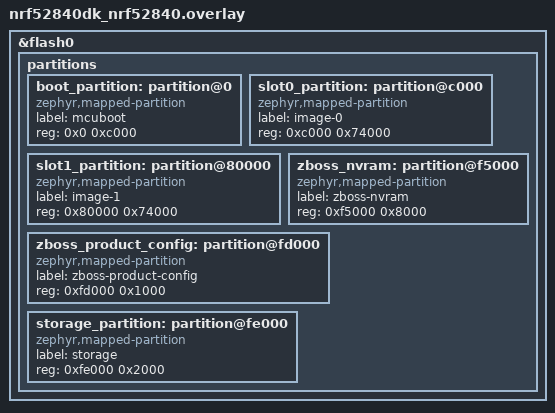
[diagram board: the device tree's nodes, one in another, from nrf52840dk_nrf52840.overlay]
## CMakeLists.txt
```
#
# Copyright (c) 2024-2026 Nordic Semiconductor ASA
#
# SPDX-License-Identifier: LicenseRef-Nordic-5-Clause
#

cmake_minimum_required(VERSION 3.20.0)

find_package(Zephyr REQUIRED HINTS $ENV{ZEPHYR_BASE})

project("Zigbee Light Switch")

target_sources(app PRIVATE
	src/main.cpp
	src/app_task_zigbee.c
	src/zboss_mem_globals.c
)

target_include_directories(app PRIVATE include)

target_sources_ifdef(CONFIG_BT_NUS app PRIVATE
	src/nus_cmd.c
)

# LTO link: zb_memconfig.o from prebuilts is plain ELF (weak gc_*); strong gc_*
# in zb_mem_config_context.h must not be LTO bytecode or ld warns about symbol size.
if(CONFIG_LTO)
	set_source_files_properties(
		src/zboss_mem_globals.c
		PROPERTIES COMPILE_OPTIONS -fno-lto
	)
endif()
```

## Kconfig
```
#
# Copyright (c) 2024-2026 Nordic Semiconductor ASA
#
# SPDX-License-Identifier: LicenseRef-Nordic-5-Clause
#

if ZIGBEE_BT_DFU

config BT_DEVICE_NAME
	default "Zigbee_Switch"

endif # ZIGBEE_BT_DFU

config MPSL_THREAD_COOP_PRIO
	default 8

menu "Zephyr Kernel"
source "Kconfig.zephyr"
endmenu

module = NUS_CMD
module-str = NUS command
source "${ZEPHYR_BASE}/subsys/logging/Kconfig.template.log_config"


config LIGHT_SWITCH_CONFIGURE_TX_POWER
	bool "Configure TX power"
	default y
	help
		Enable this option to configure TX power for the sample.

config LIGHT_SWITCH_TX_POWER
	int "TX power"
	depends on LIGHT_SWITCH_CONFIGURE_TX_POWER
	default 0
	help
		TX power level in dBm.

config LIGHT_SWITCH_LOW_POWER
	bool "Low power mode"
	default y
	depends on PM_DEVICE
	help
		Enable low power mode for the Light Switch sample.
		This enables sleepy behavior and disables LEDs for power savings.
```

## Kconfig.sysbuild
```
#
# Copyright (c) 2024-2026 Nordic Semiconductor
#
# SPDX-License-Identifier: LicenseRef-Nordic-5-Clause
#

config NRF_DEFAULT_IPC_RADIO
	default y

# Enable IEEE802.15.4 serialization to network core for Zigbee
config NETCORE_IPC_RADIO_IEEE802154
	default y if SOC_SERIES_NRF53

if BOOTLOADER_MCUBOOT

#### DFU multi-image support
config DFU_MULTI_IMAGE_PACKAGE_BUILD
	default y

config DFU_MULTI_IMAGE_PACKAGE_APP
	default y

#### DFU dual core configuration
if SOC_SERIES_NRF53

config PM_EXTERNAL_FLASH_MCUBOOT_SECONDARY
	default y

config MCUBOOT_UPDATEABLE_IMAGES
	default 2

choice MCUBOOT_MODE
	default MCUBOOT_MODE_OVERWRITE_ONLY
endchoice

config SECURE_BOOT_NETCORE
	default y

config NETCORE_APP_UPDATE
	default y

config DFU_MULTI_IMAGE_PACKAGE_NET
	default y

config MCUBOOT_NRF53_MULTI_IMAGE_UPDATE
	default y if NETCORE_APP_UPDATE

endif # SOC_SERIES_NRF53

endif # BOOTLOADER_MCUBOOT

source "${ZEPHYR_BASE}/share/sysbuild/Kconfig"
```

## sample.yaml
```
sample:
  description: Zigbee dimmable light switch based on ZBOSS stack
  name: Zigbee Light switch
common:
  tags:
    - ci_build
    - smoke
    - sysbuild
    - ci_samples_zigbee
tests:
  sample.zigbee.light_switch:
    sysbuild: true
    build_only: true
    integration_platforms:
      - nrf52840dk/nrf52840
      - nrf54l15dk/nrf54l15/cpuapp
      - nrf54lc10dk/nrf54lc10a/cpuapp
      - nrf54lm20dk/nrf54lm20b/cpuapp
      - nrf54lm20dongle/nrf54lm20b/cpuapp
    platform_allow:
      - nrf52840dk/nrf52840
      - nrf5340dk/nrf5340/cpuapp
      - nrf54l15dk/nrf54l10/cpuapp
      - nrf54l15dk/nrf54l15/cpuapp
      - nrf54lc10dk/nrf54lc10a/cpuapp
      - nrf54lm20dk/nrf54lm20a/cpuapp
      - nrf54lm20dk/nrf54lm20b/cpuapp
      - nrf54lm20dongle/nrf54lm20b/cpuapp
  sample.zigbee.light_switch.multiprotocol:
    sysbuild: true
    build_only: true
    extra_args: OVERLAY_CONFIG=overlay-multiprotocol_ble.conf
    integration_platforms:
      - nrf5340dk/nrf5340/cpuapp
      - nrf54l15dk/nrf54l15/cpuapp
      - nrf54lm20dk/nrf54lm20b/cpuapp
      - nrf54lm20dongle/nrf54lm20b/cpuapp
    platform_allow:
      - nrf52840dk/nrf52840
      - nrf5340dk/nrf5340/cpuapp
      - nrf54l15dk/nrf54l10/cpuapp
      - nrf54l15dk/nrf54l15/cpuapp
      - nrf54lc10dk/nrf54lc10a/cpuapp
      - nrf54lm20dk/nrf54lm20a/cpuapp
      - nrf54lm20dk/nrf54lm20b/cpuapp
      - nrf54lm20dongle/nrf54lm20b/cpuapp
  sample.zigbee.light_switch.io_shell:
    sysbuild: true
    build_only: true
    extra_args: light_switch_SNIPPET=io_shell
    integration_platforms:
      - nrf54lm20dongle/nrf54lm20b/cpuapp
    platform_allow:
      - nrf54lm20dongle/nrf54lm20b/cpuapp
  sample.zigbee.light_switch.with_shell:
    sysbuild: true
    build_only: true
    extra_args:
      - CONFIG_ZIGBEE_SHELL=y
      - CONFIG_ZIGBEE_SHELL_DEBUG_CMD=y
      - CONFIG_ZIGBEE_LOGGER_EP=n
      - CONFIG_ZIGBEE_SHELL_ENDPOINT=1
      - CONFIG_LOG_MODE_DEFERRED=y
      - CONFIG_ZIGBEE_TOUCHLINK_INITIATOR=y
    platform_allow:
      - nrf52840dk/nrf52840
      - nrf5340dk/nrf5340/cpuapp
      - nrf54l15dk/nrf54l10/cpuapp
      - nrf54l15dk/nrf54l15/cpuapp
      - nrf54lc10dk/nrf54lc10a/cpuapp
      - nrf54lm20dk/nrf54lm20a/cpuapp
      - nrf54lm20dk/nrf54lm20b/cpuapp
    tags:
      - no_integration
      - shell
  sample.zigbee.light_switch.fota:
    sysbuild: true
    build_only: true
    extra_args:
      - FILE_SUFFIX=fota
      - SNIPPET=zigbee_fota
    integration_platforms:
      - nrf52840dk/nrf52840
      - nrf54l15dk/nrf54l15/cpuapp
      - nrf54lc10dk/nrf54lc10a/cpuapp
      - nrf54lm20dk/nrf54lm20b/cpuapp
    platform_allow:
      - nrf52840dk/nrf52840
      - nrf5340dk/nrf5340/cpuapp
      - nrf54l15dk/nrf54l10/cpuapp
      - nrf54l15dk/nrf54l15/cpuapp
      - nrf54lc10dk/nrf54lc10a/cpuapp
      - nrf54lm20dk/nrf54lm20a/cpuapp
      - nrf54lm20dk/nrf54lm20b/cpuapp
  sample.zigbee.light_switch.fota_and_multiprotocol:
    sysbuild: true
    build_only: true
    extra_args:
      - FILE_SUFFIX=fota
      - SNIPPET=zigbee_fota
      - OVERLAY_CONFIG=overlay-multiprotocol_ble.conf
    integration_platforms:
      - nrf5340dk/nrf5340/cpuapp
      - nrf54l15dk/nrf54l15/cpuapp
      - nrf54lm20dk/nrf54lm20b/cpuapp
    platform_allow:
      - nrf5340dk/nrf5340/cpuapp
      - nrf54l15dk/nrf54l15/cpuapp
      - nrf54lm20dk/nrf54lm20a/cpuapp
      - nrf54lm20dk/nrf54lm20b/cpuapp
  sample.zigbee.light_switch.low_power:
    sysbuild: true
    build_only: true
    extra_args:
      - light_switch_SNIPPET="low_power"
    integration_platforms:
      - nrf52840dk/nrf52840
      - nrf5340dk/nrf5340/cpuapp
      - nrf54l15dk/nrf54l15/cpuapp
      - nrf54lm20dk/nrf54lm20b/cpuapp
    platform_allow:
      - nrf52840dk/nrf52840
      - nrf5340dk/nrf5340/cpuapp
      - nrf54l15dk/nrf54l10/cpuapp
      - nrf54l15dk/nrf54l15/cpuapp
      - nrf54lc10dk/nrf54lc10a/cpuapp
      - nrf54lm20dk/nrf54lm20a/cpuapp
      - nrf54lm20dk/nrf54lm20b/cpuapp
```

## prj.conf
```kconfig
#
# Copyright (c) 2024 Nordic Semiconductor ASA
#
# SPDX-License-Identifier: LicenseRef-Nordic-5-Clause
#

CONFIG_NCS_SAMPLES_DEFAULTS=y

CONFIG_UART_INTERRUPT_DRIVEN=y
CONFIG_SERIAL=y
CONFIG_GPIO=y

# Make sure printk is not printing to the UART console
CONFIG_CONSOLE=y
CONFIG_UART_CONSOLE=y

CONFIG_HEAP_MEM_POOL_SIZE=2048

CONFIG_ZIGBEE_ADD_ON=y
CONFIG_ZIGBEE_APP_UTILS=y
CONFIG_ZIGBEE_ROLE_END_DEVICE=y

# Enable DK LED and Buttons library
CONFIG_DK_LIBRARY=y
# Enable API for powering down unused RAM parts
CONFIG_RAM_POWER_DOWN_LIBRARY=y
```

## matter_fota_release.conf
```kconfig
#
# Copyright (c) 2026 Nordic Semiconductor ASA
#
# SPDX-License-Identifier: LicenseRef-Nordic-5-Clause
#
# Release configuration for combined Zigbee + Matter + Thread (PoC)
# Strips logging/console/debug and enables size optimizations.

#######################
# Release Optimizations
#######################

CONFIG_USE_SEGGER_RTT=n
CONFIG_SHELL=n
CONFIG_OPENTHREAD_SHELL=n
CONFIG_CONSOLE=n
CONFIG_UART_CONSOLE=n
CONFIG_SERIAL=n
CONFIG_UART_INTERRUPT_DRIVEN=n
CONFIG_LOG=n
CONFIG_LOG_MODE_MINIMAL=n
CONFIG_ASSERT_VERBOSE=n
CONFIG_ASSERT_NO_FILE_INFO=y
CONFIG_PRINTK=n
CONFIG_PRINTK_SYNC=n
CONFIG_BOOT_BANNER=n

# TODO: Enable LTO to decrease the flash usage after testing
# CONFIG_LTO=y
# CONFIG_ISR_TABLES_LOCAL_DECLARATION=y

CONFIG_SIZE_OPTIMIZATIONS=y
CONFIG_COMPILER_OPT="-Os"
```

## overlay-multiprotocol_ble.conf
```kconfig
#
# Copyright (c) 2024 Nordic Semiconductor ASA
#
# SPDX-License-Identifier: LicenseRef-Nordic-5-Clause
#

# BLE configuration
CONFIG_BT=y
CONFIG_BT_SMP=y
CONFIG_BT_PERIPHERAL=y
CONFIG_BT_DEVICE_NAME="Zigbee_Switch"
CONFIG_BT_DEVICE_APPEARANCE=833
CONFIG_BT_MAX_CONN=1
CONFIG_BT_MAX_PAIRED=1
CONFIG_BT_PHY_UPDATE=n

# Enable the NUS service
CONFIG_BT_NUS=y

# Enable bonding
CONFIG_SETTINGS=y
CONFIG_BT_SETTINGS=y

# BLE uses ECB peripheral directly
CONFIG_CRYPTO=n
CONFIG_CRYPTO_NRF_ECB=n
```

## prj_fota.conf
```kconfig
#
# Copyright (c) 2020 Nordic Semiconductor ASA
#
# SPDX-License-Identifier: LicenseRef-Nordic-5-Clause
#

CONFIG_NCS_SAMPLES_DEFAULTS=y

CONFIG_UART_INTERRUPT_DRIVEN=y
CONFIG_SERIAL=y
CONFIG_GPIO=y

# Make sure printk is not printing to the UART console
CONFIG_CONSOLE=y
CONFIG_UART_CONSOLE=y

CONFIG_HEAP_MEM_POOL_SIZE=2048

CONFIG_ZIGBEE_ADD_ON=y
CONFIG_ZIGBEE_APP_UTILS=y
CONFIG_ZIGBEE_ROLE_END_DEVICE=y

# Enable DK LED and Buttons library
CONFIG_DK_LIBRARY=y
# Enable API for powering down unused RAM parts
CONFIG_RAM_POWER_DOWN_LIBRARY=y


#######################
# Zigbee FOTA overlay #
#######################

# Enable Zigbee FOTA library
CONFIG_ZIGBEE_FOTA=y
CONFIG_ZIGBEE_FOTA_HW_VERSION=52
CONFIG_ZIGBEE_FOTA_ENDPOINT=5
CONFIG_MCUBOOT_IMGTOOL_SIGN_VERSION="1.2.3"
CONFIG_ZIGBEE_FOTA_COMMENT="light_switch"
CONFIG_ZIGBEE_FOTA_DOWNLOAD_RESUME=y

# Ensure an MCUboot-compatible binary is generated.
CONFIG_IMG_MANAGER=y
CONFIG_STREAM_FLASH=y
CONFIG_DFU_TARGET_MCUBOOT=y
CONFIG_IMG_ERASE_PROGRESSIVELY=y
CONFIG_ZIGBEE_FOTA_PROGRESS_EVT=y

# Increase the number of RX buffers
CONFIG_NRF_802154_RX_BUFFERS=32
```

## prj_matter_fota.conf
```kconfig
#
# Copyright (c) 2026 Nordic Semiconductor ASA
#
# SPDX-License-Identifier: LicenseRef-Nordic-5-Clause
#

CONFIG_NCS_SAMPLES_DEFAULTS=y

CONFIG_UART_INTERRUPT_DRIVEN=y
CONFIG_SERIAL=y
CONFIG_GPIO=y

CONFIG_CONSOLE=y
CONFIG_UART_CONSOLE=y

CONFIG_HEAP_MEM_POOL_SIZE=2048
CONFIG_MAIN_STACK_SIZE=10240
CONFIG_MAIN_THREAD_PRIORITY=7

#######################
# Zigbee Configuration
#######################

CONFIG_ZIGBEE_ADD_ON=y
CONFIG_ZIGBEE_APP_UTILS=y
CONFIG_ZIGBEE_APP_UTILS_LOG_LEVEL_INF=y
CONFIG_ZIGBEE_ROLE_END_DEVICE=y

CONFIG_DK_LIBRARY=y

# Touchlink initiator role for the combined Matter build
# CONFIG_ZIGBEE_TOUCHLINK_INITIATOR=y

CONFIG_RAM_POWER_DOWN_LIBRARY=y

CONFIG_ZBOSS_OSIF_LOG_LEVEL_INF=y
CONFIG_ZIGBEE_MATTER_COEXISTENCE_LOG_LEVEL_INF=y

#######################
# Matter Configuration
#######################

CONFIG_CHIP=y
CONFIG_CHIP_PROJECT_CONFIG="include/chip_project_config.h"
CONFIG_CHIP_DEVICE_PRODUCT_NAME="Matter Zigbee Light Switch"

CONFIG_NCS_SAMPLE_MATTER_ZAP_FILE_PATH="${APPLICATION_CONFIG_DIR}/src/default_zap/light_switch.zap"

CONFIG_CHIP_DEVICE_PRODUCT_ID=32772
CONFIG_STD_CPP17=y

CONFIG_CHIP_ENABLE_PAIRING_AUTOSTART=y
CONFIG_CHIP_BLE_EXT_ADVERTISING=y
CONFIG_CHIP_BLE_ADVERTISING_DURATION=60

CONFIG_BT_DEVICE_NAME="MatterZigbeeSw"

CONFIG_THREAD_NAME=y
CONFIG_MPU_STACK_GUARD=y
CONFIG_RESET_ON_FATAL_ERROR=n

# Reduce application size
CONFIG_USE_SEGGER_RTT=n

# Increase system workqueue stack for combined protocols (with Thread)
CONFIG_SYSTEM_WORKQUEUE_STACK_SIZE=6144

# Must be a preemptible priority (0–15), not cooperative (-1). With -1, ZBOSS is
# coop priority -1 and is outranked by MPSL Work (prio -8), so it never runs.
# State 128 = _THREAD_QUEUED (runnable); ZBOSS stays queued and never gets CPU.
CONFIG_ZBOSS_DEFAULT_THREAD_PRIORITY=1
CONFIG_ZBOSS_DEFAULT_THREAD_STACK_SIZE=6144

# Libc malloc arena required for Zigbee + Matter coexistence.
# - 0: no libc heap -> Matter init fails (malloc/calloc used during init).
# - -1: "all remaining RAM" -> on this build the computed heap extends past
#        valid SRAM and faults at first free().
# - Fixed value sized for Matter + Thread + Zigbee (empirical):
#   ~96 KB covers Matter CASE session, Thread buffers, and Zigbee allocations
#   without running the heap off the end of usable SRAM.
CONFIG_COMMON_LIBC_MALLOC_ARENA_SIZE=-1

## PoC Configuration ##
# Keep Matter shell disabled to avoid getopt conflicts
CONFIG_CHIP_LIB_SHELL=n
CONFIG_NCS_SAMPLE_MATTER_TEST_SHELL=n

# Radio dispatcher
CONFIG_NRF_802154_CALLBACKS_DISPATCHER=y
CONFIG_NRF_802154_DRV_REINIT_ENABLED=y

# We need it to disable ZBOSS thread
CONFIG_ZIGBEE_DEBUG_FUNCTIONS=y

CONFIG_CHIP_FACTORY_DATA_BUILD=y

# DFU over Bluetooth LE SMP
CONFIG_CHIP_DFU_OVER_BT_SMP=y
```

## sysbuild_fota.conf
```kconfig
#
# Copyright (c) 2024 Nordic Semiconductor ASA
#
# SPDX-License-Identifier: LicenseRef-Nordic-5-Clause
#

# Disable partition manager
SB_CONFIG_PARTITION_MANAGER=n

SB_CONFIG_BOOTLOADER_MCUBOOT=y
SB_CONFIG_MCUBOOT_MODE_OVERWRITE_ONLY=y
SB_CONFIG_MCUBOOT_COMPRESSED_IMAGE_SUPPORT=y
```

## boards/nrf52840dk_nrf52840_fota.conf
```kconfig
#
# Copyright (c) 2022 Nordic Semiconductor ASA
#
# SPDX-License-Identifier: LicenseRef-Nordic-5-Clause
#

# Networking
CONFIG_MPSL=y
```

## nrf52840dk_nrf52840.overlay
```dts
&flash0 {
	partitions {
		boot_partition: partition@0 {
			compatible = "zephyr,mapped-partition";
			label = "mcuboot";
			reg = <0x0 0xc000>;
		};

		slot0_partition: partition@c000 {
			compatible = "zephyr,mapped-partition";
			label = "image-0";
			reg = <0xc000 0x74000>;
		};

		slot1_partition: partition@80000 {
			compatible = "zephyr,mapped-partition";
			label = "image-1";
			reg = <0x80000 0x74000>;
		};

		zboss_nvram: partition@f5000 {
			compatible = "zephyr,mapped-partition";
			label = "zboss-nvram";
			reg = <0xf5000 0x8000>;
		};

		zboss_product_config: partition@fd000 {
			compatible = "zephyr,mapped-partition";
			label = "zboss-product-config";
			reg = <0xfd000 0x1000>;
		};

		storage_partition: partition@fe000 {
			compatible = "zephyr,mapped-partition";
			label = "storage";
			reg = <0xfe000 0x2000>;
		};
	};
};
```

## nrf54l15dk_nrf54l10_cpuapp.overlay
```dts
&cpuapp_rram {
	partitions {
		slot0_partition: partition@0 {
			compatible = "zephyr,mapped-partition";
			label = "image-0";
			reg = <0x0 0xf4000>;
		};

		zboss_nvram: partition@f4000 {
			compatible = "zephyr,mapped-partition";
			label = "zboss-nvram";
			reg = <0xf4000 0x8000>;
		};

		zboss_product_config: partition@fc000 {
			compatible = "zephyr,mapped-partition";
			label = "zboss-product-config";
			reg = <0xfc000 0x1000>;
		};
	};
};
```

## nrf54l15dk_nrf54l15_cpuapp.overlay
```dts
&cpuapp_rram {
	partitions {
		boot_partition: partition@0 {
			compatible = "zephyr,mapped-partition";
			label = "mcuboot";
			reg = <0x0 0x14000>;
		};

		slot0_partition: partition@14000 {
			compatible = "zephyr,mapped-partition";
			label = "image-0";
			reg = <0x14000 0xaf000>;
		};

		slot1_partition: partition@c3000 {
			compatible = "zephyr,mapped-partition";
			label = "image-1";
			reg = <0xc3000 0xaf000>;
		};

		zboss_nvram: partition@172000 {
			compatible = "zephyr,mapped-partition";
			label = "zboss-nvram";
			reg = <0x172000 0x8000>;
		};

		zboss_product_config: partition@17a000 {
			compatible = "zephyr,mapped-partition";
			label = "zboss-product-config";
			reg = <0x17a000 0x1000>;
		};

		storage_partition: partition@17b000 {
			compatible = "zephyr,mapped-partition";
			label = "storage";
			reg = <0x17b000 0x2000>;
		};
	};
};
```

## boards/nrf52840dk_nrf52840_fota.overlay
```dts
/*
 * Copyright (c) 2026 Nordic Semiconductor ASA
 *
 * SPDX-License-Identifier: LicenseRef-Nordic-5-Clause
 */

#include <nrf52840_partitions.dtsi>
#include <ext_flash/nrf52840dk_partitions.dtsi>

/ {
	chosen {
		ncs,zigbee-timer = &timer2;
	};
};

&timer2 {
	status = "okay";
};
```

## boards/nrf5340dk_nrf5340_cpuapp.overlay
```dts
/*
 * Copyright (c) 2025 Nordic Semiconductor ASA
 *
 * SPDX-License-Identifier: LicenseRef-Nordic-5-Clause
 */

/ {
	chosen {
		nordic,pm-ext-flash = &mx25r64;
		ncs,zigbee-timer = &timer2;
	};
};

&timer2 {
	status = "okay";
};
```

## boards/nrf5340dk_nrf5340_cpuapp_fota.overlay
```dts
/*
 * Copyright (c) 2026 Nordic Semiconductor ASA
 *
 * SPDX-License-Identifier: LicenseRef-Nordic-5-Clause
 */

#include <nrf5340_cpuapp_partitions.dtsi>
#include <ext_flash/nrf5340dk_cpuapp_partitions.dtsi>

/ {
	chosen {
		ncs,zigbee-timer = &timer2;
	};
};

&timer2 {
	status = "okay";
};
```

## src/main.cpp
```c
/*
 * Copyright (c) 2024-2026 Nordic Semiconductor ASA
 *
 * SPDX-License-Identifier: LicenseRef-Nordic-5-Clause
 */

/** @file
 *
 * @brief Zigbee light switch entry point.
 */

#include "app_task_zigbee.h"

int main(void)
{
	return ZigbeeStart();
}
```

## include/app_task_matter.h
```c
/*
 * Copyright (c) 2026 Nordic Semiconductor ASA
 *
 * SPDX-License-Identifier: LicenseRef-Nordic-5-Clause
 */

#pragma once

#include "board/board.h"

#include <platform/CHIPDeviceLayer.h>

struct k_timer;
struct Identify;

class AppTask {
public:
	static AppTask &Instance()
	{
		static AppTask sAppTask;
		return sAppTask;
	};

	CHIP_ERROR StartApp();

	void UpdateClusterState();

private:
	enum Timer : uint8_t { DimmerTrigger, Dimmer };

	CHIP_ERROR Init();

	static void DimmerTriggerEventHandler();
	static void TimerEventHandler(const Timer &event);
	static void ButtonEventHandler(Nrf::ButtonState state, Nrf::ButtonMask hasChanged);

	static void StartTimer(Timer, uint32_t);
	static void CancelTimer(Timer);
	static void UserTimerTimeoutCallback(k_timer *timer);
};
```

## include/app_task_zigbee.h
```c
/*
 * Copyright (c) 2026 Nordic Semiconductor ASA
 *
 * SPDX-License-Identifier: LicenseRef-Nordic-5-Clause
 */

#ifndef APP_TASK_ZIGBEE_H
#define APP_TASK_ZIGBEE_H 1

#include <stdint.h>

#ifdef __cplusplus
extern "C" {
#endif

int ZigbeeStart(void);

#ifdef CONFIG_ZIGBEE_MATTER_COEXISTENCE
/**
 * @brief Button handler for Zigbee in combined Matter+Zigbee builds.
 *
 * Processes button events when Zigbee protocol is active.
 * Checks protocol state and returns early if Matter is active.
 *
 * @param button_state  Bitmask containing buttons state.
 * @param has_changed   Bitmask containing buttons that changed state.
 */
void zb_button_handler(uint32_t button_state, uint32_t has_changed);

/**
 * @brief Register the Zigbee button handler with DK library.
 *
 * Must be called after Matter's Board::Init() to chain the Zigbee handler.
 */
void zb_register_button_handler(void);
#endif /* CONFIG_ZIGBEE_MATTER_COEXISTENCE */

#ifdef __cplusplus
}
#endif

#endif /* APP_TASK_ZIGBEE_H */
```

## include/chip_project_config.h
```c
/*
 * Copyright (c) 2022-2026 Nordic Semiconductor ASA
 *
 * SPDX-License-Identifier: LicenseRef-Nordic-5-Clause
 */

#pragma once

#define CHIP_CONFIG_CONTROLLER_MAX_ACTIVE_DEVICES 2

#ifndef CHIP_CONFIG_MAX_PEER_NODES
#define CHIP_CONFIG_MAX_PEER_NODES 8
#endif
```

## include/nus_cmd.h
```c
/*
 * Copyright (c) 2024 Nordic Semiconductor ASA
 *
 * SPDX-License-Identifier: LicenseRef-Nordic-5-Clause
 */

/**
 * @file nus_cmd.h
 *
 * @brief APIs for NUS Command Service.
 */

#ifndef __NUS_CMD_H__
#define __NUS_CMD_H__

#include <stddef.h>

/** @brief Type indicates function called when Bluetooth LE connection
 *         is established.
 *
 * @param[in] item pointer to work item.
 */
typedef void (*nus_connection_cb_t)(struct k_work *item);

/** @brief Type indicates function called when Bluetooth LE connection is ended.
 *
 * @param[in] item pointer to work item.
 */
typedef void (*nus_disconnection_cb_t)(struct k_work *item);

/** @brief NUS command entry.
 */
struct nus_entry {
	const char *cmd;        /**< Command string. */
	struct k_work work;     /**< Command work item. */
};

/**@brief Macro to initialise (bind) command string to work handler.
 */
#define NUS_COMMAND(_cmd, _handler)		      \
	{					      \
		.work = Z_WORK_INITIALIZER(_handler), \
		.cmd = _cmd,			      \
	}					      \

/**@brief Function to initialise NUS Command service.
 *
 * @param[in] on_connect Callback that will be called when central connects to
 *			 the NUS service.
 * @param[in] on_disconnect Callback that will be called when BLE central
 *			    disconnects from the NUS service.
 * @param[in] command_set   A pointer to an array with NUS commands.
 * @param[in] command_count Number of entries in @p command_set.
 */
void nus_cmd_init(nus_connection_cb_t on_connect,
		  nus_disconnection_cb_t on_disconnect,
		  struct nus_entry *command_set, size_t command_count);

#endif
```

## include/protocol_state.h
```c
/*
 * Copyright (c) 2024-2026 Nordic Semiconductor ASA
 *
 * SPDX-License-Identifier: LicenseRef-Nordic-5-Clause
 */

#ifndef PROTOCOL_STATE_H
#define PROTOCOL_STATE_H

#include <stdbool.h>

#ifdef __cplusplus
extern "C" {
#endif

typedef enum {
	PROTOCOL_ZIGBEE,
	PROTOCOL_MATTER
} active_protocol_t;

/**
 * @brief Load the persisted protocol state from non-volatile storage.
 *
 * Must be called once before the protocol dispatch logic runs. Safe to call
 * from multiple contexts; internal state is guarded and the underlying
 * settings subsystem is initialized at most once.
 *
 * @retval 0 on success (state loaded or default applied)
 * @retval <0 negative errno on unrecoverable storage failure
 */
int protocol_state_init(void);

/**
 * @brief Get the currently active protocol.
 * @return PROTOCOL_ZIGBEE or PROTOCOL_MATTER
 */
active_protocol_t protocol_state_get(void);

/**
 * @brief Set and persist the active protocol.
 *
 * Updates the in-RAM state and writes it to non-volatile storage so that the
 * application resumes with the same protocol after a reboot.
 *
 * @param protocol The protocol to activate.
 */
void protocol_state_set(active_protocol_t protocol);

/**
 * @brief Check if Zigbee is the active protocol.
 * @return true if Zigbee is active, false otherwise.
 */
static inline bool protocol_is_zigbee_active(void)
{
	return protocol_state_get() == PROTOCOL_ZIGBEE;
}

/**
 * @brief Check if Matter is the active protocol.
 * @return true if Matter is active, false otherwise.
 */
static inline bool protocol_is_matter_active(void)
{
	return protocol_state_get() == PROTOCOL_MATTER;
}

#ifdef __cplusplus
}
#endif

#endif /* PROTOCOL_STATE_H */
```

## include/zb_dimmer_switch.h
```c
/*
 * Copyright (c) 2024 Nordic Semiconductor ASA
 *
 * SPDX-License-Identifier: LicenseRef-Nordic-5-Clause
 */

#ifndef ZB_DIMMER_SWITCH_H
#define ZB_DIMMER_SWITCH_H 1

/**
 *  @defgroup ZB_DEFINE_DEVICE_DIMMER_SWITCH Dimmer Switch
 *  @{
 *  @details
 *      - @ref ZB_ZCL_BASIC \n
 *      - @ref ZB_ZCL_IDENTIFY \n
 *      - @ref ZB_ZCL_SCENES \n
 *      - @ref ZB_ZCL_GROUPS \n
 *      - @ref ZB_ZCL_ON_OFF \n
 *      - @ref ZB_ZCL_LEVEL_CONTROL
 */

/** Dimmer Switch Device ID */
#define ZB_DIMMER_SWITCH_DEVICE_ID 0x0104

/** Dimmer Switch device version */
#define ZB_DEVICE_VER_DIMMER_SWITCH 0

/** @cond internals_doc */

/** Dimmer Switch IN (server) clusters number */
#define ZB_DIMMER_SWITCH_IN_CLUSTER_NUM 2

/** Dimmer Switch OUT (client) clusters number */
#define ZB_DIMMER_SWITCH_OUT_CLUSTER_NUM 5

/** Dimmer switch total (IN+OUT) cluster number */
#define ZB_DIMMER_SWITCH_CLUSTER_NUM \
	(ZB_DIMMER_SWITCH_IN_CLUSTER_NUM + ZB_DIMMER_SWITCH_OUT_CLUSTER_NUM)

/** Number of attribute for reporting on Dimmer Switch device */
#define ZB_DIMMER_SWITCH_REPORT_ATTR_COUNT 0

/** @endcond */ /* internals_doc */

/**
 * @brief Declare cluster list for Dimmer Switch device
 * @param cluster_list_name - cluster list variable name
 * @param basic_server_attr_list - attribute list for Basic cluster (server role)
 * @param identify_client_attr_list - attribute list for Identify cluster (client role)
 * @param identify_server_attr_list - attribute list for Identify cluster (server role)
 * @param scenes_client_attr_list - attribute list for Scenes cluster (client role)
 * @param groups_client_attr_list - attribute list for Groups cluster (client role)
 * @param on_off_client_attr_list - attribute list for On/Off cluster (client role)
 * @param level_control_client_attr_list - attribute list for Level Control cluster (client role)
 */
#define ZB_DECLARE_DIMMER_SWITCH_CLUSTER_LIST(					  \
		cluster_list_name,						  \
		basic_server_attr_list,						  \
		identify_client_attr_list,					  \
		identify_server_attr_list,					  \
		scenes_client_attr_list,					  \
		groups_client_attr_list,					  \
		on_off_client_attr_list,					  \
		level_control_client_attr_list)					  \
zb_zcl_cluster_desc_t cluster_list_name[] =					  \
{										  \
	ZB_ZCL_CLUSTER_DESC(							  \
		ZB_ZCL_CLUSTER_ID_BASIC,					  \
		ZB_ZCL_ARRAY_SIZE(basic_server_attr_list, zb_zcl_attr_t),	  \
		(basic_server_attr_list),					  \
		ZB_ZCL_CLUSTER_SERVER_ROLE,					  \
		ZB_ZCL_MANUF_CODE_INVALID					  \
	),									  \
	ZB_ZCL_CLUSTER_DESC(							  \
		ZB_ZCL_CLUSTER_ID_IDENTIFY,					  \
		ZB_ZCL_ARRAY_SIZE(identify_server_attr_list, zb_zcl_attr_t),	  \
		(identify_server_attr_list),					  \
		ZB_ZCL_CLUSTER_SERVER_ROLE,					  \
		ZB_ZCL_MANUF_CODE_INVALID					  \
	),									  \
	ZB_ZCL_CLUSTER_DESC(							  \
		ZB_ZCL_CLUSTER_ID_IDENTIFY,					  \
		ZB_ZCL_ARRAY_SIZE(identify_client_attr_list, zb_zcl_attr_t),	  \
		(identify_client_attr_list),					  \
		ZB_ZCL_CLUSTER_CLIENT_ROLE,					  \
		ZB_ZCL_MANUF_CODE_INVALID					  \
	),									  \
	ZB_ZCL_CLUSTER_DESC(							  \
		ZB_ZCL_CLUSTER_ID_SCENES,					  \
		ZB_ZCL_ARRAY_SIZE(scenes_client_attr_list, zb_zcl_attr_t),	  \
		(scenes_client_attr_list),					  \
		ZB_ZCL_CLUSTER_CLIENT_ROLE,					  \
		ZB_ZCL_MANUF_CODE_INVALID					  \
	),									  \
	ZB_ZCL_CLUSTER_DESC(							  \
		ZB_ZCL_CLUSTER_ID_GROUPS,					  \
		ZB_ZCL_ARRAY_SIZE(groups_client_attr_list, zb_zcl_attr_t),	  \
		(groups_client_attr_list),					  \
		ZB_ZCL_CLUSTER_CLIENT_ROLE,					  \
		ZB_ZCL_MANUF_CODE_INVALID					  \
	),									  \
	ZB_ZCL_CLUSTER_DESC(							  \
		ZB_ZCL_CLUSTER_ID_ON_OFF,					  \
		ZB_ZCL_ARRAY_SIZE(on_off_client_attr_list, zb_zcl_attr_t),	  \
		(on_off_client_attr_list),					  \
		ZB_ZCL_CLUSTER_CLIENT_ROLE,					  \
		ZB_ZCL_MANUF_CODE_INVALID					  \
	),									  \
	ZB_ZCL_CLUSTER_DESC(							  \
		ZB_ZCL_CLUSTER_ID_LEVEL_CONTROL,				  \
		ZB_ZCL_ARRAY_SIZE(level_control_client_attr_list, zb_zcl_attr_t), \
		(level_control_client_attr_list),				  \
		ZB_ZCL_CLUSTER_CLIENT_ROLE,					  \
		ZB_ZCL_MANUF_CODE_INVALID					  \
	)									  \
}


/**
 * @brief Declare endpoint for Dimmer Switch device
 * @param ep_name - endpoint variable name
 * @param ep_id - endpoint ID
 * @param cluster_list - endpoint cluster list
 */
#define ZB_DECLARE_DIMMER_SWITCH_EP(ep_name, ep_id, cluster_list)		      \
	ZB_ZCL_DECLARE_DIMMER_SWITCH_SIMPLE_DESC(ep_name, ep_id,		      \
		  ZB_DIMMER_SWITCH_IN_CLUSTER_NUM, ZB_DIMMER_SWITCH_OUT_CLUSTER_NUM); \
										      \
	ZB_AF_DECLARE_ENDPOINT_DESC(ep_name, ep_id, ZB_AF_HA_PROFILE_ID, 0, NULL,     \
		ZB_ZCL_ARRAY_SIZE(cluster_list, zb_zcl_cluster_desc_t), cluster_list, \
		(zb_af_simple_desc_1_1_t *)&simple_desc_##ep_name,		      \
		0, NULL, /* No reporting ctx */					      \
		0, NULL) /* No CVC ctx */

/** @} */

#endif /* ZB_DIMMER_SWITCH_H */
```

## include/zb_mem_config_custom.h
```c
/*
 * Copyright (c) 2024 Nordic Semiconductor ASA
 *
 * SPDX-License-Identifier: LicenseRef-Nordic-5-Clause
 */

#ifndef ZB_MEM_CONFIG_CUSTOM_H
#define ZB_MEM_CONFIG_CUSTOM_H 1


#define ZB_CONFIG_ROLE_ZED
#define ZB_CONFIG_OVERALL_NETWORK_SIZE 16

/**
 * Light routing and application traffic from/to that device.
 */
#define ZB_CONFIG_LIGHT_TRAFFIC

/**
 * Simple user's application at that device: not too many relations
 * to other devices.
 */
#define ZB_CONFIG_APPLICATION_SIMPLE

/**
 * The below section is for advanced users.
 * Before modifying any values, please make sure you fully understand the
 * impact, for example by reading zb_mem_config_common.h
 */
#include "zb_mem_config_common.h"

/**
 * Now if you REALLY know what you do, you can study zb_mem_config_common.h
 * and redefine some configuration parameters, like:
 */
#if defined(CONFIG_LIGHT_SWITCH_CONFIGURE_TX_POWER) && \
	defined(CONFIG_ZIGBEE_CHANNEL_SELECTION_MODE_MULTI)
#undef ZB_CONFIG_SCHEDULER_Q_SIZE
#define ZB_CONFIG_SCHEDULER_Q_SIZE 28
#undef ZB_CONFIG_IOBUF_POOL_SIZE
#define ZB_CONFIG_IOBUF_POOL_SIZE 42
#else
#undef ZB_CONFIG_SCHEDULER_Q_SIZE
#define ZB_CONFIG_SCHEDULER_Q_SIZE 24
#endif /* CONFIG_LIGHT_SWITCH_CONFIGURE_TX_POWER && CONFIG_ZIGBEE_CHANNEL_SELECTION_MODE_MULTI */

/**
 * Increase OTA transfer time by extending the APS duplicate rejection table.
 * This value must be less than the amount of possible APS counter values (256).
 */
#undef ZB_CONFIG_APS_DUPS_TABLE_SIZE
#define ZB_CONFIG_APS_DUPS_TABLE_SIZE 64

/* Memory context definitions. */
#include "zb_mem_config_context.h"

#endif /* ZB_MEM_CONFIG_CUSTOM_H */
```

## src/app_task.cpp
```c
/*
 * Copyright (c) 2022 Nordic Semiconductor ASA
 *
 * SPDX-License-Identifier: LicenseRef-Nordic-5-Clause
 */

#include "app_task.h"

#include "light_switch.h"

#include "app/matter_init.h"
#include "app/task_executor.h"
#include "board/board.h"
#include "clusters/identify.h"

#include <setup_payload/OnboardingCodesUtil.h>

#if defined(CONFIG_ZIGBEE_MATTER_COEXISTENCE) && \
	!defined(CONFIG_ZIGBEE_MATTER_COEXISTENCE_BT_ADV_WHILE_ZIGBEE)
#include <zigbee/matter_coexistence.h>
#endif

#include <zephyr/logging/log.h>

LOG_MODULE_DECLARE(app, CONFIG_CHIP_APP_LOG_LEVEL);

using namespace ::chip;
using namespace ::chip::app;
using namespace ::chip::DeviceLayer;

namespace
{
constexpr uint32_t kDimmerTriggeredTimeout = 500;
constexpr uint32_t kDimmerInterval = 300;
constexpr EndpointId kLightSwitchEndpointId = 1;
constexpr EndpointId kLightEndpointId = 1;

k_timer sDimmerPressKeyTimer;
k_timer sDimmerTimer;

Nrf::Matter::IdentifyCluster sIdentifyCluster(kLightEndpointId);

bool sWasDimmerTriggered = false;

#define APPLICATION_BUTTON_MASK DK_BTN2_MSK

#ifdef CONFIG_CHIP_ICD_UAT_SUPPORT
#define UAT_BUTTON_MASK DK_BTN3_MSK
#endif
} /* namespace */

void AppTask::DimmerTriggerEventHandler()
{
	if (!sWasDimmerTriggered) {
		LightSwitch::GetInstance().InitiateActionSwitch(LightSwitch::Action::Toggle);
	}

	Instance().CancelTimer(Timer::Dimmer);
	Instance().CancelTimer(Timer::DimmerTrigger);
	sWasDimmerTriggered = false;
}

void AppTask::TimerEventHandler(const Timer &timerType)
{
	switch (timerType) {
	case Timer::DimmerTrigger:
		LOG_INF("Dimming started...");
		sWasDimmerTriggered = true;
		LightSwitch::GetInstance().InitiateActionSwitch(LightSwitch::Action::On);
		Instance().StartTimer(Timer::Dimmer, kDimmerInterval);
		Instance().CancelTimer(Timer::DimmerTrigger);
		break;
	case Timer::Dimmer:
		LightSwitch::GetInstance().DimmerChangeBrightness();
		break;
	default:
		break;
	}
}

void AppTask::ButtonEventHandler(Nrf::ButtonState state, Nrf::ButtonMask hasChanged)
{
	if ((APPLICATION_BUTTON_MASK & state & hasChanged)) {
		LOG_INF("Button has been pressed, keep in this state for at least 500 ms to change light sensitivity of bound lighting devices.");
		Instance().StartTimer(Timer::DimmerTrigger, kDimmerTriggeredTimeout);
	} else if ((APPLICATION_BUTTON_MASK & hasChanged)) {
		Nrf::PostTask([] { DimmerTriggerEventHandler(); });
#ifdef CONFIG_CHIP_ICD_UAT_SUPPORT
	} else if ((UAT_BUTTON_MASK & state & hasChanged)) {
		LOG_INF("ICD UserActiveMode has been triggered.");
		Server::GetInstance().GetICDManager().OnNetworkActivity();
#endif
	}
}

void AppTask::StartTimer(Timer timer, uint32_t timeoutMs)
{
	switch (timer) {
	case Timer::DimmerTrigger:
		k_timer_start(&sDimmerPressKeyTimer, K_MSEC(timeoutMs), K_NO_WAIT);
		break;
	case Timer::Dimmer:
		k_timer_start(&sDimmerTimer, K_MSEC(timeoutMs), K_MSEC(timeoutMs));
		break;
	default:
		break;
	}
}

void AppTask::CancelTimer(Timer timer)
{
	switch (timer) {
	case Timer::DimmerTrigger:
		k_timer_stop(&sDimmerPressKeyTimer);
		break;
	case Timer::Dimmer:
		k_timer_stop(&sDimmerTimer);
		break;
	default:
		break;
	}
}

void AppTask::UserTimerTimeoutCallback(k_timer *timer)
{
	if (!timer) {
		return;
	}
	Timer timerType;

	if (timer == &sDimmerPressKeyTimer) {
		timerType = Timer::DimmerTrigger;
	} else if (timer == &sDimmerTimer) {
		timerType = Timer::Dimmer;
	} else {
		return;
	}

	Nrf::PostTask([timerType]() { TimerEventHandler(timerType); });
}

CHIP_ERROR AppTask::Init()
{
	/* Initialize Matter stack */
	ReturnErrorOnFailure(Nrf::Matter::PrepareServer(Nrf::Matter::InitData{ .mPostServerInitClbk = [] {
		LightSwitch::GetInstance().Init(kLightSwitchEndpointId);
		return CHIP_NO_ERROR;
	} }));

	/* Initialize application timers */
	k_timer_init(&sDimmerPressKeyTimer, AppTask::UserTimerTimeoutCallback, nullptr);
	k_timer_init(&sDimmerTimer, AppTask::UserTimerTimeoutCallback, nullptr);

	if (!Nrf::GetBoard().Init(ButtonEventHandler)) {
		LOG_ERR("User interface initialization failed.");
		return CHIP_ERROR_INCORRECT_STATE;
	}

	/* Register Matter event handler that controls the connectivity status LED based on the captured Matter network
	 * state. */
	ReturnErrorOnFailure(Nrf::Matter::RegisterEventHandler(Nrf::Board::DefaultMatterEventHandler, 0));

	ReturnErrorOnFailure(sIdentifyCluster.Init());

	ReturnErrorOnFailure(Nrf::Matter::StartServer());

#if defined(CONFIG_ZIGBEE_MATTER_COEXISTENCE) && \
	!defined(CONFIG_ZIGBEE_MATTER_COEXISTENCE_BT_ADV_WHILE_ZIGBEE)
	zigbee_matter_coexistence_signal_matter_board_init();
#endif

	return CHIP_NO_ERROR;
}

CHIP_ERROR AppTask::StartApp()
{
	ReturnErrorOnFailure(Init());

	while (true) {
		Nrf::DispatchNextTask();
	}

	return CHIP_NO_ERROR;
}
```

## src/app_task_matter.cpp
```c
/*
 * Copyright (c) 2026 Nordic Semiconductor ASA
 *
 * SPDX-License-Identifier: LicenseRef-Nordic-5-Clause
 */

#include "app_task_matter.h"

#include "light_switch.h"

#include "app/matter_init.h"
#include "app/task_executor.h"
#include "board/board.h"
#include "clusters/identify.h"

#include <setup_payload/OnboardingCodesUtil.h>

#if defined(CONFIG_ZIGBEE_MATTER_COEXISTENCE)
#include <zigbee/matter_coexistence.h>
#endif

#include <zephyr/logging/log.h>

LOG_MODULE_DECLARE(app, CONFIG_CHIP_APP_LOG_LEVEL);

using namespace ::chip;
using namespace ::chip::app;
using namespace ::chip::DeviceLayer;

namespace
{
constexpr uint32_t kDimmerTriggeredTimeout = 500;
constexpr uint32_t kDimmerInterval = 300;
constexpr EndpointId kLightSwitchEndpointId = 1;
constexpr EndpointId kLightEndpointId = 1;

k_timer sDimmerPressKeyTimer;
k_timer sDimmerTimer;

Nrf::Matter::IdentifyCluster sIdentifyCluster(kLightEndpointId);

bool sWasDimmerTriggered = false;

#define APPLICATION_BUTTON_MASK DK_BTN2_MSK

#ifdef CONFIG_CHIP_ICD_UAT_SUPPORT
#define UAT_BUTTON_MASK DK_BTN3_MSK
#endif
} /* namespace */

void AppTask::DimmerTriggerEventHandler()
{
	if (!sWasDimmerTriggered) {
		LightSwitch::GetInstance().InitiateActionSwitch(LightSwitch::Action::Toggle);
	}

	Instance().CancelTimer(Timer::Dimmer);
	Instance().CancelTimer(Timer::DimmerTrigger);
	sWasDimmerTriggered = false;
}

void AppTask::TimerEventHandler(const Timer &timerType)
{
	switch (timerType) {
	case Timer::DimmerTrigger:
		LOG_INF("Dimming started...");
		sWasDimmerTriggered = true;
		LightSwitch::GetInstance().InitiateActionSwitch(LightSwitch::Action::On);
		Instance().StartTimer(Timer::Dimmer, kDimmerInterval);
		Instance().CancelTimer(Timer::DimmerTrigger);
		break;
	case Timer::Dimmer:
		LightSwitch::GetInstance().DimmerChangeBrightness();
		break;
	default:
		break;
	}
}

void AppTask::ButtonEventHandler(Nrf::ButtonState state, Nrf::ButtonMask hasChanged)
{
	if ((APPLICATION_BUTTON_MASK & state & hasChanged)) {
		LOG_INF("Button has been pressed, keep in this state for at least 500 ms to change light sensitivity of bound lighting devices.");
		Instance().StartTimer(Timer::DimmerTrigger, kDimmerTriggeredTimeout);
	} else if ((APPLICATION_BUTTON_MASK & hasChanged)) {
		Nrf::PostTask([] { DimmerTriggerEventHandler(); });
#ifdef CONFIG_CHIP_ICD_UAT_SUPPORT
	} else if ((UAT_BUTTON_MASK & state & hasChanged)) {
		LOG_INF("ICD UserActiveMode has been triggered.");
		Server::GetInstance().GetICDManager().OnNetworkActivity();
#endif
	}
}

void AppTask::StartTimer(Timer timer, uint32_t timeoutMs)
{
	switch (timer) {
	case Timer::DimmerTrigger:
		k_timer_start(&sDimmerPressKeyTimer, K_MSEC(timeoutMs), K_NO_WAIT);
		break;
	case Timer::Dimmer:
		k_timer_start(&sDimmerTimer, K_MSEC(timeoutMs), K_MSEC(timeoutMs));
		break;
	default:
		break;
	}
}

void AppTask::CancelTimer(Timer timer)
{
	switch (timer) {
	case Timer::DimmerTrigger:
		k_timer_stop(&sDimmerPressKeyTimer);
		break;
	case Timer::Dimmer:
		k_timer_stop(&sDimmerTimer);
		break;
	default:
		break;
	}
}

void AppTask::UserTimerTimeoutCallback(k_timer *timer)
{
	if (!timer) {
		return;
	}
	Timer timerType;

	if (timer == &sDimmerPressKeyTimer) {
		timerType = Timer::DimmerTrigger;
	} else if (timer == &sDimmerTimer) {
		timerType = Timer::Dimmer;
	} else {
		return;
	}

	Nrf::PostTask([timerType]() { TimerEventHandler(timerType); });
}

CHIP_ERROR AppTask::Init()
{
	/* Initialize Matter stack */
	Nrf::Matter::InitData initData{};
	initData.mPostServerInitClbk = [] {
		LightSwitch::GetInstance().Init(kLightSwitchEndpointId);
		return CHIP_NO_ERROR;
	};
#if defined(CONFIG_ZIGBEE_MATTER_COEXISTENCE)
	initData.mPreServerInitClbk = []() -> CHIP_ERROR {
		zigbee_matter_coexistence_pre_server_init();
		return CHIP_NO_ERROR;
	};
#endif
	ReturnErrorOnFailure(Nrf::Matter::PrepareServer(initData));

	/* Initialize application timers */
	k_timer_init(&sDimmerPressKeyTimer, AppTask::UserTimerTimeoutCallback, nullptr);
	k_timer_init(&sDimmerTimer, AppTask::UserTimerTimeoutCallback, nullptr);

	if (!Nrf::GetBoard().Init(ButtonEventHandler)) {
		LOG_ERR("User interface initialization failed.");
		return CHIP_ERROR_INCORRECT_STATE;
	}

	/* Register Matter event handler that controls the connectivity status LED based on the captured Matter network
	 * state. */
	ReturnErrorOnFailure(Nrf::Matter::RegisterEventHandler(Nrf::Board::DefaultMatterEventHandler, 0));

	ReturnErrorOnFailure(sIdentifyCluster.Init());

	ReturnErrorOnFailure(Nrf::Matter::StartServer());

#if defined(CONFIG_ZIGBEE_MATTER_COEXISTENCE)
	zigbee_matter_coexistence_on_server_started();
#endif

	return CHIP_NO_ERROR;
}

CHIP_ERROR AppTask::StartApp()
{
	ReturnErrorOnFailure(Init());

	while (true) {
		Nrf::DispatchNextTask();
	}

	return CHIP_NO_ERROR;
}
```

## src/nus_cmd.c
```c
/*
 * Copyright (c) 2024 Nordic Semiconductor ASA
 *
 * SPDX-License-Identifier: LicenseRef-Nordic-5-Clause
 */
#include <zephyr/kernel.h>
#include <zephyr/bluetooth/gatt.h>
#include <zephyr/bluetooth/hci.h>
#include <zephyr/bluetooth/uuid.h>
#include <bluetooth/services/nus.h>
#include <zephyr/logging/log.h>
#include <zephyr/settings/settings.h>

#include "nus_cmd.h"

LOG_MODULE_REGISTER(nus_cmd, CONFIG_NUS_CMD_LOG_LEVEL);

#define DEVICE_NAME        CONFIG_BT_DEVICE_NAME
#define DEVICE_NAME_LEN    (sizeof(DEVICE_NAME) - 1)

static void connected(struct bt_conn *conn, uint8_t err);
static void disconnected(struct bt_conn *conn, uint8_t reason);
static void auth_passkey_display(struct bt_conn *conn, unsigned int passkey);
static void auth_cancel(struct bt_conn *conn);
static void pairing_complete(struct bt_conn *conn, bool bonded);
static void pairing_failed(struct bt_conn *conn, enum bt_security_err reason);
static void __attribute__((unused))
security_changed(struct bt_conn *conn, bt_security_t level,
		 enum bt_security_err err);

static struct bt_conn_auth_cb conn_auth_callbacks = {
	.passkey_display = auth_passkey_display,
	.cancel = auth_cancel,
};

static struct bt_conn_auth_info_cb conn_auth_info_callbacks = {
	.pairing_complete = pairing_complete,
	.pairing_failed = pairing_failed
};

static struct bt_conn_cb conn_callbacks = {
	.connected = connected,
	.disconnected = disconnected,
	COND_CODE_1(CONFIG_BT_SMP, (.security_changed = security_changed), ())
};

static const struct bt_data ad[] = {
	BT_DATA_BYTES(BT_DATA_FLAGS, (BT_LE_AD_GENERAL | BT_LE_AD_NO_BREDR)),
	BT_DATA(BT_DATA_NAME_COMPLETE, DEVICE_NAME, DEVICE_NAME_LEN),
};

static const struct bt_data sd[] = {
	BT_DATA_BYTES(BT_DATA_UUID128_ALL, BT_UUID_NUS_VAL),
};

static struct k_work on_connect_work;
static struct k_work on_disconnect_work;
static struct bt_conn *current_conn;
static struct nus_entry *nus_commands;
static size_t nus_commands_count;

static void connected(struct bt_conn *conn, uint8_t err)
{
	if (err) {
		LOG_ERR("Connection failed (err %u)", err);
		return;
	}

	LOG_INF("Connected");
	current_conn = bt_conn_ref(conn);

	k_work_submit(&on_connect_work);
}

static void disconnected(struct bt_conn *conn, uint8_t reason)
{
	LOG_INF("Disconnected (reason %u)", reason);

	if (current_conn) {
		bt_conn_unref(current_conn);
		current_conn = NULL;

		k_work_submit(&on_disconnect_work);
	}
}

static char *ble_addr(struct bt_conn *conn)
{
	static char addr[BT_ADDR_LE_STR_LEN];

	bt_addr_le_to_str(bt_conn_get_dst(conn), addr, sizeof(addr));

	return addr;
}

static void __attribute__((unused))
security_changed(struct bt_conn *conn, bt_security_t level,
		 enum bt_security_err err)
{
	char *addr = ble_addr(conn);

	if (!err) {
		LOG_INF("Security changed: %s level %u", addr, level);
	} else {
		LOG_INF("Security failed: %s level %u err %d", addr,
			level, err);
	}
}

static void auth_passkey_display(struct bt_conn *conn, unsigned int passkey)
{
	char *addr = ble_addr(conn);

	LOG_INF("Passkey for %s: %06u", addr, passkey);
}

static void auth_cancel(struct bt_conn *conn)
{
	char *addr = ble_addr(conn);

	LOG_INF("Pairing cancelled: %s", addr);
}

static void pairing_complete(struct bt_conn *conn, bool bonded)
{
	char *addr = ble_addr(conn);

	LOG_INF("Pairing completed: %s, bonded: %d", addr, bonded);
}

static void pairing_failed(struct bt_conn *conn, enum bt_security_err reason)
{
	char *addr = ble_addr(conn);

	LOG_INF("Pairing failed conn: %s, reason %d", addr, reason);
}

static int ble_utils_init(struct bt_nus_cb *nus_clbs,
			  nus_connection_cb_t on_connect,
			  nus_disconnection_cb_t on_disconnect)
{
	int ret;

	k_work_init(&on_connect_work, on_connect);
	k_work_init(&on_disconnect_work, on_disconnect);

	bt_conn_cb_register(&conn_callbacks);

	if (IS_ENABLED(CONFIG_BT_SMP)) {
		ret = bt_conn_auth_cb_register(&conn_auth_callbacks);
		if (ret) {
			LOG_ERR("Failed to register authorization callbacks.");
			goto end;
		}

		ret = bt_conn_auth_info_cb_register(&conn_auth_info_callbacks);
		if (ret) {
			LOG_ERR("Failed to register authorization info callbacks.");
			goto end;
		}
	}

	ret = bt_enable(NULL);
	if (ret) {
		LOG_ERR("Bluetooth initialization failed (error: %d)", ret);
		goto end;
	}

	LOG_INF("Bluetooth initialized");

	if (IS_ENABLED(CONFIG_BT_SETTINGS)) {
		ret = settings_load_subtree("bt");
		if (ret) {
			LOG_ERR("Failed to load Bluetooth settings (error: %d)", ret);
			goto end;
		}
	} else if (IS_ENABLED(CONFIG_SETTINGS)) {
		ret = settings_load();
		if (ret) {
			LOG_ERR("Failed to load settings (error: %d)", ret);
			goto end;
		}
	}

	ret = bt_nus_init(nus_clbs);
	if (ret) {
		LOG_ERR("Failed to initialize UART service (error: %d)", ret);
		goto end;
	}

	ret = bt_le_adv_start(BT_LE_ADV_CONN_FAST_1, ad, ARRAY_SIZE(ad), sd,
			      ARRAY_SIZE(sd));
	if (ret) {
		LOG_ERR("Advertising failed to start (error: %d)", ret);
		goto end;
	}

end:
	return ret;
}

static void nus_command_handler(struct bt_conn *conn,
				const uint8_t *const data, uint16_t length)
{
	LOG_HEXDUMP_DBG(data, length, "NUS recv:");

	for (size_t i = 0; i < nus_commands_count; i++) {
		struct nus_entry *p = &nus_commands[i];

		if ((length >= strlen(p->cmd)) &&
		    (!strncmp(p->cmd, (const char *)data, strlen(p->cmd)))) {
			LOG_DBG("Matched cmd: %s", p->cmd);
			k_work_submit(&p->work);
			return;
		}
	}

	LOG_HEXDUMP_WRN(data, length, "Command unrecognized");
}

void nus_cmd_init(nus_connection_cb_t on_connect,
		  nus_disconnection_cb_t on_disconnect,
		  struct nus_entry *command_set, size_t command_count)
{
	struct bt_nus_cb nus_clbs = {
		.received = nus_command_handler,
		.sent = NULL,
	};

	nus_commands = command_set;
	nus_commands_count = command_count;

	ble_utils_init(&nus_clbs, on_connect, on_disconnect);
}
```
